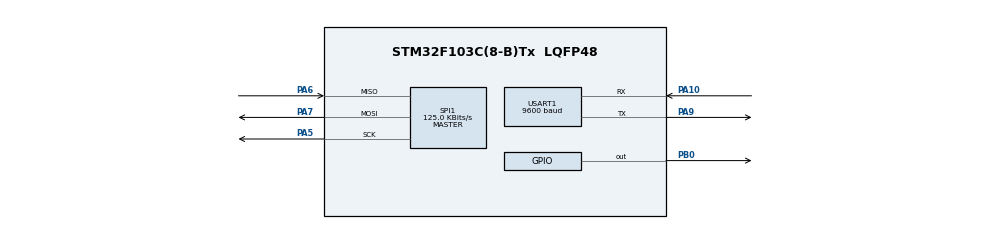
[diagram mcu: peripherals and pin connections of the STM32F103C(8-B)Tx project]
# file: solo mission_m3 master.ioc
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Mcu.Family=STM32F1
Mcu.Name=STM32F103C(8-B)Tx
Mcu.Package=LQFP48
NVIC.PriorityGroup=NVIC_PRIORITYGROUP_4
PA10.Mode=Asynchronous
PA10.Signal=USART1_RX
PA5.Mode=Full_Duplex_Master
PA5.Signal=SPI1_SCK
PA6.Mode=Full_Duplex_Master
PA6.Signal=SPI1_MISO
PA7.Mode=Full_Duplex_Master
PA7.Signal=SPI1_MOSI
PA9.Mode=Asynchronous
PA9.Signal=USART1_TX
PB0.Signal=GPIO_Output
ProjectManager.HeapSize=0x200
ProjectManager.StackSize=0x400
ProjectManager.TargetToolchain=STM32CubeIDE
RCC.APB1Freq_Value=8000000
RCC.APB2Freq_Value=8000000
RCC.SYSCLKSource=RCC_SYSCLKSOURCE_PLLCLK
SPI1.BaudRatePrescaler=SPI_BAUDRATEPRESCALER_64
SPI1.CalculateBaudRate=125.0 KBits/s
SPI1.Direction=SPI_DIRECTION_2LINES
SPI1.Mode=SPI_MODE_MASTER
SPI1.VirtualType=VM_MASTER
USART1.BaudRate=9600
USART1.VirtualMode=VM_ASYNC
VP_SYS_VS_ND.Mode=No_Debug
board=custom

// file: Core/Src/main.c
/* USER CODE BEGIN Header */
/**
  ******************************************************************************
  * @file           : main.c
  * @brief          : Main program body
  ******************************************************************************
  * @attention
  *
  * Copyright (c) 2026 STMicroelectronics.
  * All rights reserved.
  *
  * This software is licensed under terms that can be found in the LICENSE file
  * in the root directory of this software component.
  * If no LICENSE file comes with this software, it is provided AS-IS.
  *
  ******************************************************************************
  */
/* USER CODE END Header */
#include "main.h"

SPI_HandleTypeDef hspi1;

UART_HandleTypeDef huart1;

void SystemClock_Config(void);
static void MX_GPIO_Init(void);
static void MX_SPI1_Init(void);
static void MX_USART1_UART_Init(void);

/* USER CODE BEGIN 0 */
uint8_t tx[3] = {0};
uint8_t rx[3] = {0};
uint8_t input;
/* USER CODE END 0 */

int main(void)
{

  /* MCU Configuration--------------------------------------------------------*/

  /* Reset of all peripherals, Initializes the Flash interface and the Systick. */
  HAL_Init();

  /* Configure the system clock */
  SystemClock_Config();

  /* Initialize all configured peripherals */
  MX_GPIO_Init();
  MX_SPI1_Init();
  MX_USART1_UART_Init();

  /* Infinite loop */
  while (1)
  	{
  	HAL_UART_Receive(&huart1, &input, 1, HAL_MAX_DELAY);
  	if (input >= '1' && input <= '5')
  		{
  		uint16_t currentId = 0x1000 + (input - '0');
  	 	tx[0]=(currentId>>8) & 0xFF;
  	 	tx[1]= currentId & 0xFF;
  	 	tx[2]=0x00;

  	 	HAL_GPIO_WritePin(GPIOB, GPIO_PIN_0, GPIO_PIN_RESET);

  	 	HAL_SPI_Transmit(&hspi1, tx, 3, HAL_MAX_DELAY);

  	 	HAL_GPIO_WritePin(GPIOB, GPIO_PIN_0, GPIO_PIN_SET);

  	 	// spi cycle 2

  	 	tx[0] = 0x00;
  	 	tx[1] = 0x00;
  	 	tx[2] = 0x00;

  	 	HAL_GPIO_WritePin(GPIOB, GPIO_PIN_0, GPIO_PIN_RESET);

  	 	HAL_SPI_TransmitReceive(&hspi1, tx, rx, 3, HAL_MAX_DELAY);

  	 	HAL_GPIO_WritePin(GPIOB, GPIO_PIN_0, GPIO_PIN_SET);

  	 	uint32_t message = ((uint32_t)rx[0]<<16)|((uint32_t)rx[1]<<8)|rx[2];
  	 	uint16_t volt = message>>12 ;
  	 	uint16_t speed =message & 0xFFF;

  	 	// format the message sent to terminal

  	 	char debug[50];

  	 	int debug_length = snprintf(debug, sizeof(debug),
  	 	        "RX: %02X %02X %02X\r\n",
  	 	        rx[0], rx[1], rx[2]);

  	 	HAL_UART_Transmit(&huart1,
  	 	                  (uint8_t*)debug,
  	 	                  debug_length,
  	 	                  HAL_MAX_DELAY);

  	 	char Tmessage[64];
  	 	int length = snprintf(Tmessage,sizeof(Tmessage),
  	 		"voltage = %u.%u | Speed = %u\r\n", volt/10,volt%10,speed);
  	 	HAL_UART_Transmit(&huart1,(uint8_t*)Tmessage,length, HAL_MAX_DELAY);
  	 	HAL_Delay(500);

  		}
  	}
}

void SystemClock_Config(void)
{
  RCC_OscInitTypeDef RCC_OscInitStruct = {0};
  RCC_ClkInitTypeDef RCC_ClkInitStruct = {0};

  /** Initializes the RCC Oscillators according to the specified parameters
  * in the RCC_OscInitTypeDef structure.
  */
  RCC_OscInitStruct.OscillatorType = RCC_OSCILLATORTYPE_HSI;
  RCC_OscInitStruct.HSIState = RCC_HSI_ON;
  RCC_OscInitStruct.HSICalibrationValue = RCC_HSICALIBRATION_DEFAULT;
  RCC_OscInitStruct.PLL.PLLState = RCC_PLL_ON;
  RCC_OscInitStruct.PLL.PLLSource = RCC_PLLSOURCE_HSI_DIV2;
  RCC_OscInitStruct.PLL.PLLMUL = RCC_PLL_MUL2;
  if (HAL_RCC_OscConfig(&RCC_OscInitStruct) != HAL_OK)
  {
    Error_Handler();
  }

  /** Initializes the CPU, AHB and APB buses clocks
  */
  RCC_ClkInitStruct.ClockType = RCC_CLOCKTYPE_HCLK|RCC_CLOCKTYPE_SYSCLK
                              |RCC_CLOCKTYPE_PCLK1|RCC_CLOCKTYPE_PCLK2;
  RCC_ClkInitStruct.SYSCLKSource = RCC_SYSCLKSOURCE_PLLCLK;
  RCC_ClkInitStruct.AHBCLKDivider = RCC_SYSCLK_DIV1;
  RCC_ClkInitStruct.APB1CLKDivider = RCC_HCLK_DIV1;
  RCC_ClkInitStruct.APB2CLKDivider = RCC_HCLK_DIV1;

  if (HAL_RCC_ClockConfig(&RCC_ClkInitStruct, FLASH_LATENCY_0) != HAL_OK)
  {
    Error_Handler();
  }
}

static void MX_SPI1_Init(void)
{

  /* SPI1 parameter configuration*/
  hspi1.Instance = SPI1;
  hspi1.Init.Mode = SPI_MODE_MASTER;
  hspi1.Init.Direction = SPI_DIRECTION_2LINES;
  hspi1.Init.DataSize = SPI_DATASIZE_8BIT;
  hspi1.Init.CLKPolarity = SPI_POLARITY_LOW;
  hspi1.Init.CLKPhase = SPI_PHASE_1EDGE;
  hspi1.Init.NSS = SPI_NSS_SOFT;
  hspi1.Init.BaudRatePrescaler = SPI_BAUDRATEPRESCALER_64;
  hspi1.Init.FirstBit = SPI_FIRSTBIT_MSB;
  hspi1.Init.TIMode = SPI_TIMODE_DISABLE;
  hspi1.Init.CRCCalculation = SPI_CRCCALCULATION_DISABLE;
  hspi1.Init.CRCPolynomial = 10;
  if (HAL_SPI_Init(&hspi1) != HAL_OK)
  {
    Error_Handler();
  }

}

static void MX_USART1_UART_Init(void)
{

  huart1.Instance = USART1;
  huart1.Init.BaudRate = 9600;
  huart1.Init.WordLength = UART_WORDLENGTH_8B;
  huart1.Init.StopBits = UART_STOPBITS_1;
  huart1.Init.Parity = UART_PARITY_NONE;
  huart1.Init.Mode = UART_MODE_TX_RX;
  huart1.Init.HwFlowCtl = UART_HWCONTROL_NONE;
  huart1.Init.OverSampling = UART_OVERSAMPLING_16;
  if (HAL_UART_Init(&huart1) != HAL_OK)
  {
    Error_Handler();
  }

}

static void MX_GPIO_Init(void)
{
  GPIO_InitTypeDef GPIO_InitStruct = {0};

  /* GPIO Ports Clock Enable */
  __HAL_RCC_GPIOA_CLK_ENABLE();
  __HAL_RCC_GPIOB_CLK_ENABLE();

  /*Configure GPIO pin Output Level */
  HAL_GPIO_WritePin(GPIOB, GPIO_PIN_0, GPIO_PIN_RESET);

  /*Configure GPIO pin : PB0 */
  GPIO_InitStruct.Pin = GPIO_PIN_0;
  GPIO_InitStruct.Mode = GPIO_MODE_OUTPUT_PP;
  GPIO_InitStruct.Pull = GPIO_NOPULL;
  GPIO_InitStruct.Speed = GPIO_SPEED_FREQ_LOW;
  HAL_GPIO_Init(GPIOB, &GPIO_InitStruct);

}

void Error_Handler(void)
{
  __disable_irq();
  while (1)
  {
  }
}
